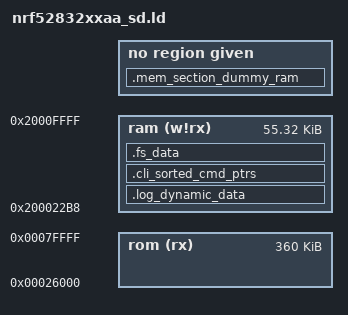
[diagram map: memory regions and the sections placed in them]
/*
 * Copyright (C) 2016 Freie Universität Berlin
 *
 * This file is subject to the terms and conditions of the GNU Lesser
 * General Public License v2.1. See the file LICENSE in the top level
 * directory for more details.
 */

/**
 * @addtogroup      cpu_nrf52
 * @{
 *
 * @file
 * @brief           Memory definitions for the NRF52832XXAA
 *
 * @author          Hauke Petersen <hauke.petersen@fu-berlin.de>
 *
 * @}
 */

GROUP(-lgcc -lc -lnosys)

MEMORY
{
    rom (rx)    : ORIGIN = 0x00026000, LENGTH = 0x5A000
    ram (w!rx)  : ORIGIN = 0x200022b8, LENGTH = 0x0dd48
}

SECTIONS
{
  . = ALIGN(4);
  .mem_section_dummy_ram :
  {
  }
  .log_dynamic_data :
  {
    PROVIDE(__start_log_dynamic_data = .);
    KEEP(*(SORT(.log_dynamic_data*)))
    PROVIDE(__stop_log_dynamic_data = .);
  } > ram
  .cli_sorted_cmd_ptrs :
  {
    PROVIDE(__start_cli_sorted_cmd_ptrs = .);
    KEEP(*(.cli_sorted_cmd_ptrs))
    PROVIDE(__stop_cli_sorted_cmd_ptrs = .);
  } > ram
  .fs_data :
  {
    PROVIDE(__start_fs_data = .);
    KEEP(*(.fs_data))
    PROVIDE(__stop_fs_data = .);
  } > ram

} INSERT AFTER .relocate;

SECTIONS
{
  .mem_section_dummy_rom :
  {
  }
  .sdh_soc_observers :
  {
    PROVIDE(__start_sdh_soc_observers = .);
    KEEP(*(SORT(.sdh_soc_observers*)))
    PROVIDE(__stop_sdh_soc_observers = .);
  } > rom
  .pwr_mgmt_data :
  {
    PROVIDE(__start_pwr_mgmt_data = .);
    KEEP(*(SORT(.pwr_mgmt_data*)))
    PROVIDE(__stop_pwr_mgmt_data = .);
  } > rom
  .sdh_ble_observers :
  {
    PROVIDE(__start_sdh_ble_observers = .);
    KEEP(*(SORT(.sdh_ble_observers*)))
    PROVIDE(__stop_sdh_ble_observers = .);
  } > rom
  .log_const_data :
  {
    PROVIDE(__start_log_const_data = .);
    KEEP(*(SORT(.log_const_data*)))
    PROVIDE(__stop_log_const_data = .);
  } > rom
    .nrf_balloc :
  {
    PROVIDE(__start_nrf_balloc = .);
    KEEP(*(.nrf_balloc))
    PROVIDE(__stop_nrf_balloc = .);
  } > rom
  .sdh_state_observers :
  {
    PROVIDE(__start_sdh_state_observers = .);
    KEEP(*(SORT(.sdh_state_observers*)))
    PROVIDE(__stop_sdh_state_observers = .);
  } > rom
  .sdh_stack_observers :
  {
    PROVIDE(__start_sdh_stack_observers = .);
    KEEP(*(SORT(.sdh_stack_observers*)))
    PROVIDE(__stop_sdh_stack_observers = .);
  } > rom
  .sdh_req_observers :
  {
    PROVIDE(__start_sdh_req_observers = .);
    KEEP(*(SORT(.sdh_req_observers*)))
    PROVIDE(__stop_sdh_req_observers = .);
  } > rom
    .nrf_queue :
  {
    PROVIDE(__start_nrf_queue = .);
    KEEP(*(.nrf_queue))
    PROVIDE(__stop_nrf_queue = .);
  } > rom
    .cli_command :
  {
    PROVIDE(__start_cli_command = .);
    KEEP(*(.cli_command))
    PROVIDE(__stop_cli_command = .);
  } > rom
  .crypto_data :
  {
    PROVIDE(__start_crypto_data = .);
    KEEP(*(SORT(.crypto_data*)))
    PROVIDE(__stop_crypto_data = .);
  } > rom

  __data_start__ = ORIGIN(ram);

} INSERT AFTER .text

INCLUDE cortexm_base.ld
